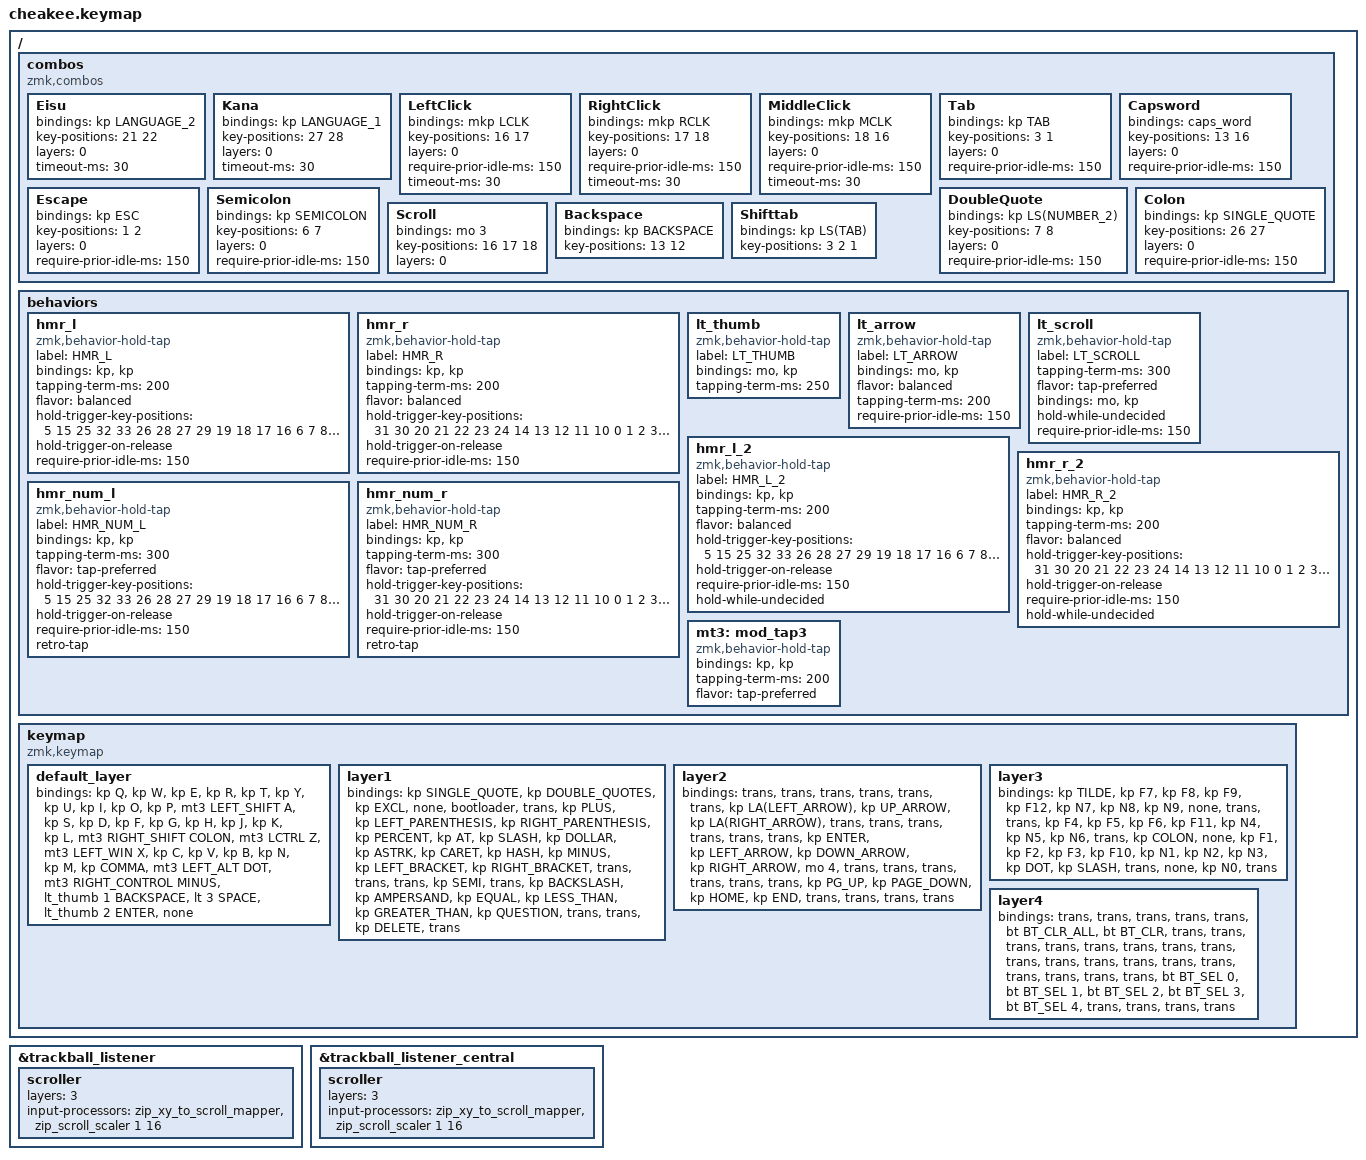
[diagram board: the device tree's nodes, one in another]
#include <input/processors.dtsi>
#include <dt-bindings/zmk/input_transform.h>
#include <behaviors.dtsi>
#include <dt-bindings/zmk/bt.h>
#include <dt-bindings/zmk/keys.h>
#include <dt-bindings/zmk/pointing.h>

/ {
    combos {
        compatible = "zmk,combos";

        Eisu {
            bindings = <&kp LANGUAGE_2>;
            key-positions = <21 22>;
            layers = <0>;
            timeout-ms = <30>;
        };

        Kana {
            bindings = <&kp LANGUAGE_1>;
            key-positions = <27 28>;
            layers = <0>;
            timeout-ms = <30>;
        };

        LeftClick {
            bindings = <&mkp LCLK>;
            key-positions = <16 17>;
            layers = <0>;
            require-prior-idle-ms = <150>;
            timeout-ms = <30>;
        };

        RightClick {
            bindings = <&mkp RCLK>;
            key-positions = <17 18>;
            layers = <0>;
            require-prior-idle-ms = <150>;
            timeout-ms = <30>;
        };

        MiddleClick {
            bindings = <&mkp MCLK>;
            key-positions = <18 16>;
            layers = <0>;
            require-prior-idle-ms = <150>;
            timeout-ms = <30>;
        };

        Tab {
            bindings = <&kp TAB>;
            key-positions = <3 1>;
            layers = <0>;
            require-prior-idle-ms = <150>;
        };

        Capsword {
            bindings = <&caps_word>;
            key-positions = <13 16>;
            layers = <0>;
            require-prior-idle-ms = <150>;
        };

        Escape {
            bindings = <&kp ESC>;
            key-positions = <1 2>;
            layers = <0>;
            require-prior-idle-ms = <150>;
        };

        DoubleQuote {
            bindings = <&kp LS(NUMBER_2)>;
            key-positions = <7 8>;
            layers = <0>;
            require-prior-idle-ms = <150>;
        };

        Semicolon {
            bindings = <&kp SEMICOLON>;
            key-positions = <6 7>;
            layers = <0>;
            require-prior-idle-ms = <150>;
        };

        Colon {
            bindings = <&kp SINGLE_QUOTE>;
            key-positions = <26 27>;
            layers = <0>;
            require-prior-idle-ms = <150>;
        };

        Scroll {
            bindings = <&mo 3>;
            key-positions = <16 17 18>;
            layers = <0>;
        };

        Backspace {
            bindings = <&kp BACKSPACE>;
            key-positions = <13 12>;
        };

        Shifttab {
            bindings = <&kp LS(TAB)>;
            key-positions = <3 2 1>;
        };
    };

    behaviors {
        hmr_l: hmr_l {
            compatible = "zmk,behavior-hold-tap";
            label = "HMR_L";
            bindings = <&kp>, <&kp>;

            #binding-cells = <2>;
            tapping-term-ms = <200>;
            flavor = "balanced";
            hold-trigger-key-positions = <5 15 25 32 33 26 28 27 29 19 18 17 16 6 7 8 9>;
            hold-trigger-on-release;
            require-prior-idle-ms = <150>;
        };

        hmr_r: hmr_r {
            compatible = "zmk,behavior-hold-tap";
            label = "HMR_R";
            bindings = <&kp>, <&kp>;

            #binding-cells = <2>;
            tapping-term-ms = <200>;
            flavor = "balanced";
            hold-trigger-key-positions = <31 30 20 21 22 23 24 14 13 12 11 10 0 1 2 3 4>;
            hold-trigger-on-release;
            require-prior-idle-ms = <150>;
        };

        lt_thumb: lt_thumb {
            compatible = "zmk,behavior-hold-tap";
            label = "LT_THUMB";
            bindings = <&mo>, <&kp>;

            #binding-cells = <2>;
            tapping-term-ms = <250>;
        };

        lt_arrow: lt_arrow {
            compatible = "zmk,behavior-hold-tap";
            label = "LT_ARROW";
            bindings = <&mo>, <&kp>;

            #binding-cells = <2>;
            flavor = "balanced";
            tapping-term-ms = <200>;
            require-prior-idle-ms = <150>;
        };

        lt_scroll: lt_scroll {
            compatible = "zmk,behavior-hold-tap";
            label = "LT_SCROLL";
            #binding-cells = <2>;
            tapping-term-ms = <300>;
            flavor = "tap-preferred";
            bindings = <&mo>, <&kp>;

            hold-while-undecided;
            require-prior-idle-ms = <150>;
        };

        hmr_l_2: hmr_l_2 {
            compatible = "zmk,behavior-hold-tap";
            label = "HMR_L_2";
            bindings = <&kp>, <&kp>;

            #binding-cells = <2>;
            tapping-term-ms = <200>;
            flavor = "balanced";
            hold-trigger-key-positions = <5 15 25 32 33 26 28 27 29 19 18 17 16 6 7 8 9>;
            hold-trigger-on-release;
            require-prior-idle-ms = <150>;
            hold-while-undecided;
        };

        hmr_r_2: hmr_r_2 {
            compatible = "zmk,behavior-hold-tap";
            label = "HMR_R_2";
            bindings = <&kp>, <&kp>;

            #binding-cells = <2>;
            tapping-term-ms = <200>;
            flavor = "balanced";
            hold-trigger-key-positions = <31 30 20 21 22 23 24 14 13 12 11 10 0 1 2 3 4>;
            hold-trigger-on-release;
            require-prior-idle-ms = <150>;
            hold-while-undecided;
        };

        hmr_num_l: hmr_num_l {
            compatible = "zmk,behavior-hold-tap";
            label = "HMR_NUM_L";
            bindings = <&kp>, <&kp>;

            #binding-cells = <2>;
            tapping-term-ms = <300>;
            flavor = "tap-preferred";
            hold-trigger-key-positions = <5 15 25 32 33 26 28 27 29 19 18 17 16 6 7 8 9>;
            hold-trigger-on-release;
            require-prior-idle-ms = <150>;
            retro-tap;
        };

        hmr_num_r: hmr_num_r {
            compatible = "zmk,behavior-hold-tap";
            label = "HMR_NUM_R";
            bindings = <&kp>, <&kp>;

            #binding-cells = <2>;
            tapping-term-ms = <300>;
            flavor = "tap-preferred";
            hold-trigger-key-positions = <31 30 20 21 22 23 24 14 13 12 11 10 0 1 2 3 4>;
            hold-trigger-on-release;
            require-prior-idle-ms = <150>;
            retro-tap;
        };

        mt3: mod_tap3 {
            compatible = "zmk,behavior-hold-tap";
            bindings = <&kp>, <&kp>;

            #binding-cells = <2>;
            tapping-term-ms = <200>;
            flavor = "tap-preferred";
        };
    };

    keymap {
        compatible = "zmk,keymap";

        default_layer {
            bindings = <
&kp Q  &kp W  &kp E  &kp R  &kp T  &kp Y  &kp U  &kp I  &kp O  &kp P  &mt3 LEFT_SHIFT A  &kp S  &kp D  &kp F  &kp G  &kp H  &kp J  &kp K  &kp L  &mt3 RIGHT_SHIFT COLON  &mt3 LCTRL Z  &mt3 LEFT_WIN X  &kp C  &kp V  &kp B  &kp N  &kp M  &kp COMMA  &mt3 LEFT_ALT DOT  &mt3 RIGHT_CONTROL MINUS  &lt_thumb 1 BACKSPACE  &lt 3 SPACE  &lt_thumb 2 ENTER  &none
            >;
        };

        layer1 {
            bindings = <
&kp SINGLE_QUOTE  &kp DOUBLE_QUOTES  &kp EXCL  &none  &bootloader  &trans  &kp PLUS  &kp LEFT_PARENTHESIS  &kp RIGHT_PARENTHESIS  &kp PERCENT  &kp AT  &kp SLASH  &kp DOLLAR  &kp ASTRK  &kp CARET  &kp HASH  &kp MINUS  &kp LEFT_BRACKET  &kp RIGHT_BRACKET  &trans  &trans  &trans  &kp SEMI  &trans  &kp BACKSLASH  &kp AMPERSAND  &kp EQUAL  &kp LESS_THAN  &kp GREATER_THAN  &kp QUESTION  &trans  &trans  &kp DELETE  &trans
            >;
        };

        layer2 {
            bindings = <
&trans  &trans  &trans  &trans  &trans  &trans  &kp LA(LEFT_ARROW)  &kp UP_ARROW  &kp LA(RIGHT_ARROW)  &trans  &trans  &trans  &trans  &trans  &trans  &kp ENTER  &kp LEFT_ARROW  &kp DOWN_ARROW  &kp RIGHT_ARROW  &mo 4  &trans  &trans  &trans  &trans  &trans  &trans  &kp PG_UP  &kp PAGE_DOWN  &kp HOME  &kp END  &trans  &trans  &trans  &trans
            >;
        };

        layer3 {
            bindings = <
&kp TILDE  &kp F7  &kp F8  &kp F9  &kp F12  &kp N7  &kp N8  &kp N9  &none  &trans  &trans  &kp F4  &kp F5  &kp F6  &kp F11  &kp N4  &kp N5  &kp N6  &trans  &kp COLON  &none  &kp F1  &kp F2  &kp F3  &kp F10  &kp N1  &kp N2  &kp N3  &kp DOT  &kp SLASH  &trans  &none  &kp N0  &trans
            >;
        };

        layer4 {
            bindings = <
&trans  &trans  &trans  &trans  &trans  &bt BT_CLR_ALL  &bt BT_CLR  &trans  &trans  &trans  &trans  &trans  &trans  &trans  &trans  &trans  &trans  &trans  &trans  &trans  &trans  &trans  &trans  &trans  &trans  &bt BT_SEL 0  &bt BT_SEL 1  &bt BT_SEL 2  &bt BT_SEL 3  &bt BT_SEL 4  &trans  &trans  &trans  &trans
            >;
        };
    };
};

&trackball_listener {
    scroller {
        layers = <3>;
        input-processors = <&zip_xy_to_scroll_mapper &zip_scroll_scaler 1 16>;
    };
};

&trackball_listener_central {
    scroller {
        layers = <3>;
        input-processors = <&zip_xy_to_scroll_mapper &zip_scroll_scaler 1 16>;
    };
};
